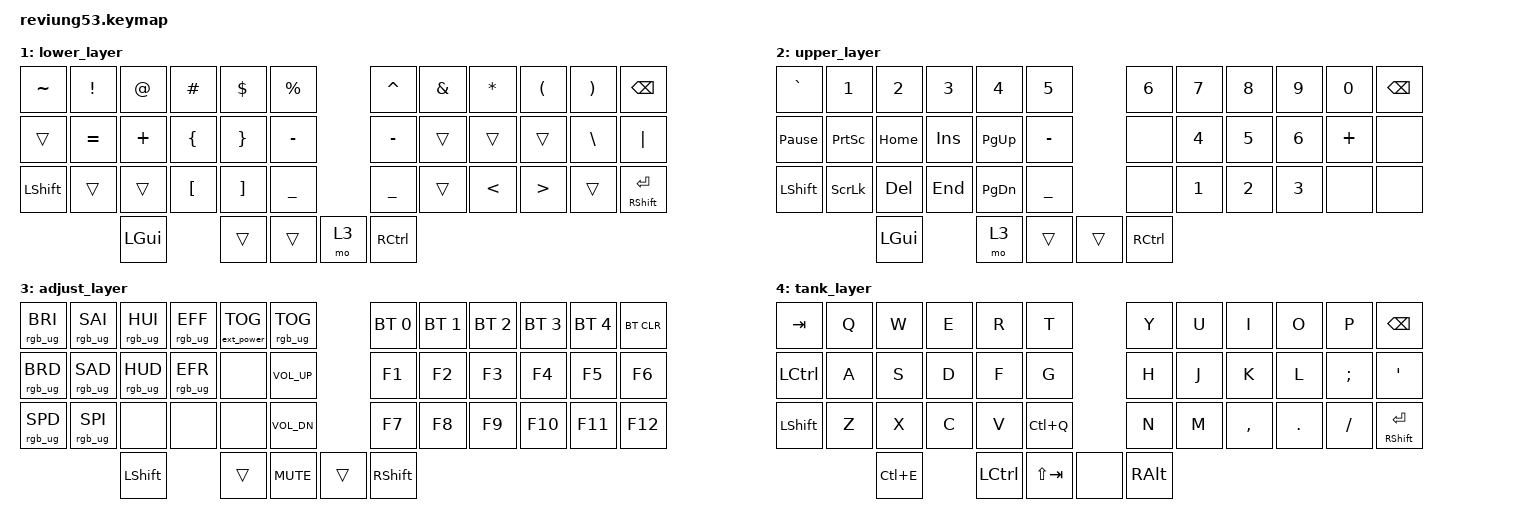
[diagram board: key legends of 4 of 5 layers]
#include <behaviors.dtsi>
#include <dt-bindings/zmk/keys.h>
#include <dt-bindings/zmk/bt.h>
#include <dt-bindings/zmk/rgb.h>
#include <dt-bindings/zmk/ext_power.h>


/ {
    combos {
        compatible = "zmk,combos";
        
        combo_del {
            timeout-ms = <40>;
            key-positions = <20 21>;
            bindings = <&kp DEL>;
        };
    };
};

/ {
        keymap {
                compatible = "zmk,keymap";

            default_layer {
// -------------------------------------------------------------------------------------
//              | ESC | F1  | F2  | F3  | F4  | PP  | VD  | VU  | MUTE |  TANK_TOG  |
// | TAB  |  Q  |  W  |  E  |  R  |  T  |  Y  |  U  |  I  |  O  |  P   |  BKSP    |
//   | CAPS |  A  |  S  |  D  |  F  |  G  |  H  |  J  |  K  |  L  |      |  RET     |
//     | LSFT |  Z  |  X  |  C  |  V  |  B  |  N  |  M  |  /  |     |      |  RSFT    |
// | LCTL | LGUI | LALT |     | SPC(LWR)  |  SPC(RSE) |     | RALT | RCTL | RGUI |

            bindings = <
                     &kp ESC  &kp F1  &kp F2  &kp F3  &rgb_ug RGB_EFF  &kp C_PP  &kp C_VOL_DN    &kp C_VOL_UP  &kp C_MUTE   &rgb_ug RGB_BRI
    &kp TAB   &kp Q  &kp W    &kp E   &kp R   &kp T   &kp Y   &kp U   &kp I     &kp O   &kp P         &kp BSPC                    
    &kp CAPS  &kp A  &kp S    &kp D   &kp F   &kp G   &kp H   &kp J   &kp K     &kp L   &kp RET       &none
    &kp LSHFT &kp Z  &kp X    &kp C   &kp V   &kp B   &kp N   &kp M   &kp FSLH  &kp RSHFT             &none
    &kp LCTRL  &kp LGUI  &kp LALT            &lt 1 SPACE &lt 2 SPACE             &kp RALT  &kp RGUI   &kp RCTRL   
            >;
                };

                lower_layer {
// ----------------------------------------------------------------------------------
// |  ~    |  !  |  @  |  #  |  $  |  %  | xxxxx |  ^  |  &  |  *  |  (  |  )  |    BKSP   |
// |       |  =  |  +  |  {  |  }  |  -  | xxxxx |  -  |     |     |     |  \  |    "|"    |
// | SHIFT |     |     |  [  |  ]  |  _  | xxxxx |  _  |     |  <  |  >  |     | SHFT(RET) |
//                          | GUI  |     |     | ADJ | CTRL |
                        bindings = <
   &kp TILDE     &kp EXCL   &kp AT    &kp HASH    &kp DLLR  &kp PRCNT         &kp CARET  &kp AMPS  &kp STAR  &kp LPAR  &kp RPAR  &kp BSPC
   &trans         &kp EQUAL  &kp PLUS  &kp LBRC    &kp RBRC  &kp MINUS         &kp MINUS  &trans    &trans    &trans    &kp BSLH  &kp PIPE
   &kp LSHFT      &trans     &trans    &kp LBKT    &kp RBKT  &kp UNDER         &kp UNDER  &trans    &kp LT    &kp GT    &trans    &mt RSHFT RET
                                                   &kp LGUI  &trans  &trans  &mo 3  &kp RCTRL
                        >;
                };

                upper_layer {
// -------------------------------------------------------------------------------------
//              | ESC | F1  | F2  | F3  | F4  | PP  | VD  | VU  | MUTE |  DEL     |
// | TAB  |  1  |  2  |  3  |  4  |  5  |  6  |  7  |  8  |  9  |  0   |  BKSP    |
//   | CAPS |  A  |  S  |  D  |  F  |  G  |  4  |  5  |  6  |     |      |  RET     |
//     | LSFT |  Z  |  X  |  C  |  V  |  B  |  1  |  2  |  3  |     |      |  RSHFT   |
// | LCTL | LGUI | LALT |     | SPC(LWR)  |  SPC(RSE) |     | RALT | RCTL | RGUI |
                        bindings = <
   &kp GRAVE        &kp N1       &kp N2    &kp N3   &kp N4     &kp N5                &kp N6       &kp N7    &kp N8    &kp N9    &kp N0    &kp BSPC
   &kp PAUSE_BREAK  &kp PSCRN    &kp HOME  &kp INS  &kp PG_UP  &kp MINUS             &none        &kp N4    &kp N5    &kp N6    &kp PLUS  &none
   &kp LSHFT        &kp SLCK     &kp DEL   &kp END  &kp PG_DN  &kp UNDER             &none        &kp N1    &kp N2    &kp N3    &none     &none
                                      &kp LGUI      &mo 3       &trans        &trans      &kp RCTRL
                        >;
                };

                adjust_layer {
// -------------------------------------------------------------------------------------
//              | ESC | F1  | F2  | F3  | F4  | PP  | VD  | VU  | MUTE |  DEL     |
// | TAB  |  Q  |  W  |  E  |  R  |  T  |  Y  |  U  |  I  |  O  |  P   |  BKSP    |
//   | CAPS |  A  |  S  |  D  |  F  |  G  |  H  |  J  |  K  |  L  |      |  RET     |
//     | LSFT |  Z  |  X  |  C  |  V  |  B  |  N  |  M  |  /  |     |      |  RSFT    |
// | LCTL | LGUI | LALT |     | SPC(LWR)  |  SPC(RSE) |     | RALT | RCTL | RGUI |
                        bindings = <
   &rgb_ug RGB_BRI &rgb_ug RGB_SAI &rgb_ug RGB_HUI &rgb_ug RGB_EFF &ext_power EP_TOG &rgb_ug RGB_TOG           &bt BT_SEL 0 &bt BT_SEL 1 &bt BT_SEL 2 &bt BT_SEL 3 &bt BT_SEL 4 &bt BT_CLR
   &rgb_ug RGB_BRD &rgb_ug RGB_SAD &rgb_ug RGB_HUD &rgb_ug RGB_EFR &none             &kp C_VOL_UP              &kp F1    &kp F2    &kp F3    &kp F4    &kp F5    &kp F6
   &rgb_ug RGB_SPD &rgb_ug RGB_SPI &none           &none           &none             &kp C_VOL_DN              &kp F7    &kp F8    &kp F9    &kp F10   &kp F11   &kp F12
                            &kp LSHFT      &trans       &kp C_MUTE      &trans    &kp RSHFT
                        >;
                };
                tank_layer {
// -------------------------------------------------------------------------------------
// |  TAB |  Q  |  W  |  E  |  R  |  T  | xxxxx |  Y  |  U   |  I  |  O  |  P  |   BKSP    |
// | CTRL |  A  |  S  |  D  |  F  |  G  | xxxxx |  H  |  J   |  K  |  L  |  ;  |    '      |
// | SHFT |  Z  |  X  |  C  |  V  |  B  | xxxxx |  N  |  M   |  ,  |  .  |  /  | SHFT(RET) |
//                     | CTRL+E | CTRL | SHFT+TAB |     | ALT |
                        bindings = <
   &kp TAB    &kp Q   &kp W    &kp E    &kp R  &kp T      &kp Y  &kp U  &kp I      &kp O    &kp P     &kp BSPC
   &kp LCTRL  &kp A  &kp S  &kp D  &kp F  &kp G      &kp H  &kp J  &kp K      &kp L    &kp SEMI  &kp SQT
   &kp LSHFT  &kp Z   &kp X   &kp C    &kp V  &kp LC(Q)      &kp N  &kp M  &kp COMMA  &kp DOT  &kp FSLH  &mt RSHFT RET
                          &kp LC(E)  &kp LCTRL   &kp LS(TAB)  &none  &kp RALT
                        >;
                };
        };
};
